# RT584ZCM33 register map
Series: ARMv8-M Mainline; File version: 1.0
CPU: CM33 r0p0, little endian, MPU, no FPU, VTOR, 3 interrupt priority bits
Registers are 32-bit, read-write, reset 0x0 unless marked. A register's access mark holds for its fields unless they carry their own. Offsets are from the block's base; [hi:lo] are bit positions.

## I2C_M0_Non-Secure — I2C_M0 Non-Secure Register block
Base 0x4002B000
Same registers: I2C_M1_Non-Secure 0x4002C000, I2C_M0_Secure 0x5002B000, I2C_M1_Secure 0x5002C000
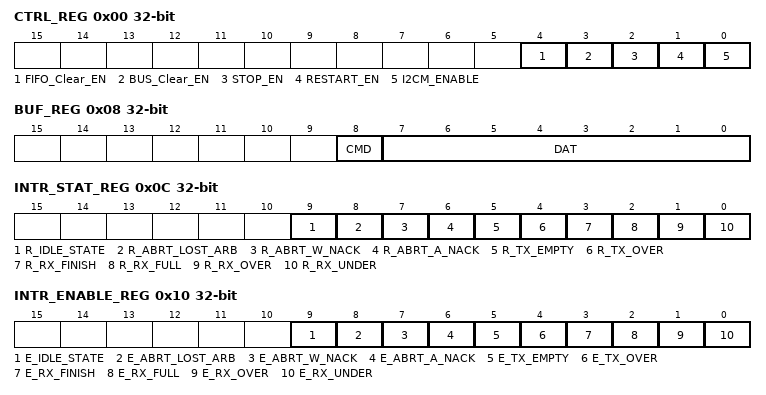
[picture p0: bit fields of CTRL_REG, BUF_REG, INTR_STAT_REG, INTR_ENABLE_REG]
0x00 CTRL_REG — ctrl
  [4] FIFO_Clear_EN — If the I2C transaction is abort for some error conditions, we could clear the transmit and receive buffers by setting FIFO_Clear_EN. - Write (Set): a value of 1 to force to clear the transmit and receive buffers. - Read (Status): a value of 0 to indicate the process of FIFO clear is done.
    0=B_4 (If the I2C transaction is abort for some error conditions, we could clear the transmit and receive buffers by setting FIFO_Clear_EN. - Write (Set): a value of 1 to force to clear the transmit and receive buffers. - Read (Status): a value of 0 to indicate the process of FIFO clear is done.)
  [3] BUS_Clear_EN — If the data line (SDA) is stuck LOW driven by device, enable this bit to send nine clock pulses by the master engine. BUS_Clear_EN is set by software and clear by hardware. - Write (Set): a value of 1 to force engine to send nine clock pulses. - Read (Status): a value of 0 to indicate the bus clear process is done.
    0=B_3 (If the data line (SDA) is stuck LOW driven by device, enable this bit to send nine clock pulses by the master engine. BUS_Clear_EN is set by software and clear by hardware. - Write (Set): a value of 1 to force engine to send nine clock pulses. - Read (Status): a value of 0 to indicate the bus clear process is done.)
  [2] STOP_EN — Force to stop I2C transaction after transmit buffer empty. STOP_EN is set by software and clear by hardware. - Write (Set): a value of 1 to indicate the I2C transaction would be terminated after transmit buffer empty. - Read (Status): a value of 0 to indicate all the transaction is done, I2C bus is stop and back to IDLE state.
    0=B_2 (Force to stop I2C transaction after transmit buffer empty. STOP_EN is set by software and clear by hardware. - Write (Set): a value of 1 to indicate the I2C transaction would be terminated after transmit buffer empty. - Read (Status): a value of 0 to indicate all the transaction is done, I2C bus is stop and back to IDLE state.)
  [1] RESTART_EN — Enable -RESTART- function. 0: disable 1: enable
    0=B_1_ITEM0 (disable); 1=B_1_ITEM1 (enable)
  [0] I2CM_ENABLE — Enable I2CM engine. 0: disable 1: enable
    0=B_0_ITEM0 (disable); 1=B_0_ITEM1 (enable)
0x04 TAR_REG reset 0x50 — tar
  [6:0] target_address — 7-bit I2C Target Address
    0=B_0_to_6 (7-bit I2C Target Address)
0x08 BUF_REG — buf
  [8] CMD wo — This bit controls whether a read or a write is performed. 0: write 1: read When a command is entered in the TX FIFO, this bit distinguishes the write and read commands.
    0=B_8_ITEM0 (write); 1=B_8_ITEM1 (read)
  [7:0] DAT — This register contains the data to be transmitted or received on the I2C bus. If you are writing to this register and want to perform a read, bits [7:0] (DAT) are ignored by the I2CM. However, when you read this register, these bits return the value of data received on the I2C interface.
    0=B_0_to_7 (This register contains the data to be transmitted or received on the I2C bus. If you are writing to this register and want to perform a read, bits [7:0] (DAT) are ignored by the I2CM. However, when you read this register, these bits return the value of data received on the I2C interface.)
0x0C INTR_STAT_REG ro — intr stat
  [9] R_IDLE_STATE — See INTR_RAW_STAT register for a detailed description of these bits.
    0=B_9 (See INTR_RAW_STAT register for a detailed description of these bits.)
  [8] R_ABRT_LOST_ARB — See INTR_RAW_STAT register for a detailed description of these bits.
    0=B_8 (See INTR_RAW_STAT register for a detailed description of these bits.)
  [7] R_ABRT_W_NACK — See INTR_RAW_STAT register for a detailed description of these bits.
    0=B_7 (See INTR_RAW_STAT register for a detailed description of these bits.)
  [6] R_ABRT_A_NACK — See INTR_RAW_STAT register for a detailed description of these bits.
    0=B_6 (See INTR_RAW_STAT register for a detailed description of these bits.)
  [5] R_TX_EMPTY — See INTR_RAW_STAT register for a detailed description of these bits.
    0=B_5 (See INTR_RAW_STAT register for a detailed description of these bits.)
  [4] R_TX_OVER — See INTR_RAW_STAT register for a detailed description of these bits.
    0=B_4 (See INTR_RAW_STAT register for a detailed description of these bits.)
  [3] R_RX_FINISH — See INTR_RAW_STAT register for a detailed description of these bits.
    0=B_3 (See INTR_RAW_STAT register for a detailed description of these bits.)
  [2] R_RX_FULL — See INTR_RAW_STAT register for a detailed description of these bits.
    0=B_2 (See INTR_RAW_STAT register for a detailed description of these bits.)
  [1] R_RX_OVER — See INTR_RAW_STAT register for a detailed description of these bits.
    0=B_1 (See INTR_RAW_STAT register for a detailed description of these bits.)
  [0] R_RX_UNDER — See INTR_RAW_STAT register for a detailed description of these bits.
    0=B_0 (See INTR_RAW_STAT register for a detailed description of these bits.)
0x10 INTR_ENABLE_REG — intr enable
  [9] E_IDLE_STATE — These bits enable their corresponding interrupt status bits in the INTR_STAT register.
    0=B_9 (These bits enable their corresponding interrupt status bits in the INTR_STAT register.)
  [8] E_ABRT_LOST_ARB — These bits enable their corresponding interrupt status bits in the INTR_STAT register.
    0=B_8 (These bits enable their corresponding interrupt status bits in the INTR_STAT register.)
  [7] E_ABRT_W_NACK — These bits enable their corresponding interrupt status bits in the INTR_STAT register.
    0=B_7 (These bits enable their corresponding interrupt status bits in the INTR_STAT register.)
  [6] E_ABRT_A_NACK — These bits enable their corresponding interrupt status bits in the INTR_STAT register.
    0=B_6 (These bits enable their corresponding interrupt status bits in the INTR_STAT register.)
  [5] E_TX_EMPTY — These bits enable their corresponding interrupt status bits in the INTR_STAT register.
    0=B_5 (These bits enable their corresponding interrupt status bits in the INTR_STAT register.)
  [4] E_TX_OVER — These bits enable their corresponding interrupt status bits in the INTR_STAT register.
    0=B_4 (These bits enable their corresponding interrupt status bits in the INTR_STAT register.)
  [3] E_RX_FINISH — These bits enable their corresponding interrupt status bits in the INTR_STAT register.
    0=B_3 (These bits enable their corresponding interrupt status bits in the INTR_STAT register.)
  [2] E_RX_FULL — These bits enable their corresponding interrupt status bits in the INTR_STAT register.
    0=B_2 (These bits enable their corresponding interrupt status bits in the INTR_STAT register.)
  [1] E_RX_OVER — These bits enable their corresponding interrupt status bits in the INTR_STAT register.
    0=B_1 (These bits enable their corresponding interrupt status bits in the INTR_STAT register.)
  [0] E_RX_UNDER — These bits enable their corresponding interrupt status bits in the INTR_STAT register.
    0=B_0 (These bits enable their corresponding interrupt status bits in the INTR_STAT register.)
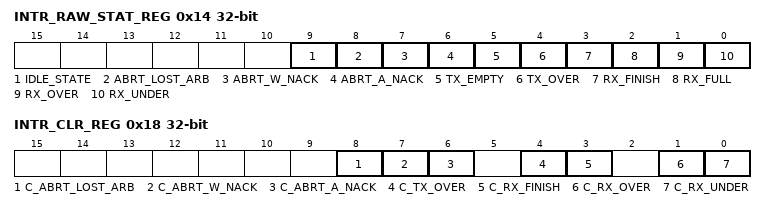
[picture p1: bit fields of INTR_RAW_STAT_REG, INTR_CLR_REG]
0x14 INTR_RAW_STAT_REG ro — intr raw stat
  [9] IDLE_STATE — This bit captures I2CM in IDLE state and stays set until it is cleared.
    0=B_9 (This bit captures I2CM in IDLE state and stays set until it is cleared.)
  [8] ABRT_LOST_ARB — This bit is set to 1 when I2CM has lost arbitration.
    0=B_8 (This bit is set to 1 when I2CM has lost arbitration.)
  [7] ABRT_W_NACK — This bit is set to 1 when I2CM did not receive an acknowledge from the remote slave for the write data.
    0=B_7 (This bit is set to 1 when I2CM did not receive an acknowledge from the remote slave for the write data.)
  [6] ABRT_A_NACK — This bit is set to 1 when the address sent was not acknowledged by any slave.
    0=B_6 (This bit is set to 1 when the address sent was not acknowledged by any slave.)
  [5] TX_EMPTY — This bit is set to 1 when the transmit buffer is empty. It is automatically cleared by hardware when the transmit buffer is not empty.
    0=B_5 (This bit is set to 1 when the transmit buffer is empty. It is automatically cleared by hardware when the transmit buffer is not empty.)
  [4] TX_OVER — Set when the transmit buffer is full and the processor attempts to issue another I2C command by writing to the BUF register.
    0=B_4 (Set when the transmit buffer is full and the processor attempts to issue another I2C command by writing to the BUF register.)
  [3] RX_FINISH — Set when the transmit buffer is empty and the last byte of read data is put into the receive buffer.
    0=B_3 (Set when the transmit buffer is empty and the last byte of read data is put into the receive buffer.)
  [2] RX_FULL — Set when the receive buffer is full. It is automatically cleared by hardware when receive buffer is not full.
    0=B_2 (Set when the receive buffer is full. It is automatically cleared by hardware when receive buffer is not full.)
  [1] RX_OVER — Set if the receive buffer is completely filled and an additional byte is received from an external I2C device. The I2CM acknowledges this, but any data bytes received after the FIFO is full are lost.
    0=B_1 (Set if the receive buffer is completely filled and an additional byte is received from an external I2C device. The I2CM acknowledges this, but any data bytes received after the FIFO is full are lost.)
  [0] RX_UNDER — Set if the processor attempts to read the receive buffer when it is empty by reading from the BUF register.
    0=B_0 (Set if the processor attempts to read the receive buffer when it is empty by reading from the BUF register.)
0x18 INTR_CLR_REG wo — intr clr
  [8] C_ABRT_LOST_ARB — Write 1 to clear R_ ABRT_LOST_ARB and ABRT_LOST_ARB.
    0=B_8 (Write 1 to clear R_ ABRT_LOST_ARB and ABRT_LOST_ARB.)
  [7] C_ABRT_W_NACK — Write 1 to clear R_ ABRT_W_NACK and ABRT_W_NACK.
    0=B_7 (Write 1 to clear R_ ABRT_W_NACK and ABRT_W_NACK.)
  [6] C_ABRT_A_NACK — Write 1 to clear R_ ABRT_A_NACK and ABRT_A_NACK.
    0=B_6 (Write 1 to clear R_ ABRT_A_NACK and ABRT_A_NACK.)
  [4] C_TX_OVER — Write 1 to clear R_ TX_OVER and TX_OVER.
    0=B_4 (Write 1 to clear R_ TX_OVER and TX_OVER.)
  [3] C_RX_FINISH — Write 1 to clear R_ RX_FINISH and RX_FINISH.
    0=B_3 (Write 1 to clear R_ RX_FINISH and RX_FINISH.)
  [1] C_RX_OVER — Write 1 to clear R_ RX_OVER and RX_OVER.
    0=B_1 (Write 1 to clear R_ RX_OVER and RX_OVER.)
  [0] C_RX_UNDER — Write 1 to clear R_ RX_UNDER and RX_UNDER.
    0=B_0 (Write 1 to clear R_ RX_UNDER and RX_UNDER.)
0x1C SCLK_GEN_REG — sclk gen
  [13:0] SclkDiv — I2C Source Clock Divider.
